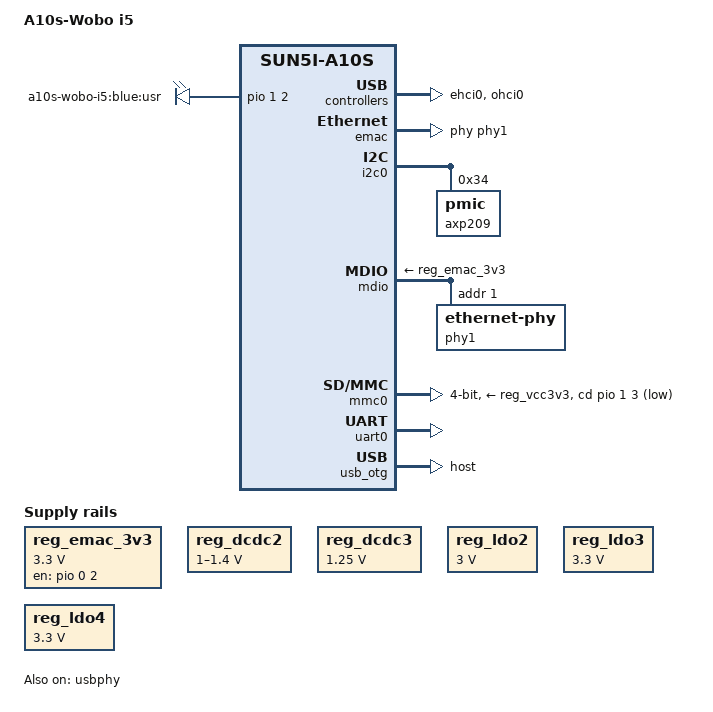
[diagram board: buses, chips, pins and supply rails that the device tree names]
/dts-v1/;
#include "sun5i-a10s.dtsi"
#include "sunxi-common-regulators.dtsi"
#include <dt-bindings/gpio/gpio.h>
#include <dt-bindings/interrupt-controller/irq.h>
/ {
	model = "A10s-Wobo i5";
	compatible = "wobo,a10s-wobo-i5", "allwinner,sun5i-a10s";
	aliases {
		serial0 = &uart0;
	};
	chosen {
		stdout-path = "serial0:115200n8";
	};
	leds {
		compatible = "gpio-leds";
		led {
			label = "a10s-wobo-i5:blue:usr";
			gpios = <&pio 1 2 GPIO_ACTIVE_HIGH>;
			default-state = "on";
		};
	};
	reg_emac_3v3: emac-3v3 {
		compatible = "regulator-fixed";
		regulator-name = "emac-3v3";
		regulator-min-microvolt = <3300000>;
		regulator-max-microvolt = <3300000>;
		startup-delay-us = <20000>;
		enable-active-high;
		gpio = <&pio 0 2 GPIO_ACTIVE_HIGH>;
	};
};
&cpu0 {
	cpu-supply = <&reg_dcdc2>;
};
&ehci0 {
	status = "okay";
};
&emac {
	pinctrl-names = "default";
	pinctrl-0 = <&emac_pd_pins>;
	phy-handle = <&phy1>;
	status = "okay";
};
&emac_sram {
	status = "okay";
};
&i2c0 {
	status = "okay";
	axp209: pmic@34 {
		reg = <0x34>;
		interrupts = <0>;
	};
};
#include "axp209.dtsi"
&mdio {
	phy-supply = <&reg_emac_3v3>;
	status = "okay";
	phy1: ethernet-phy@1 {
		reg = <1>;
	};
};
&mmc0 {
	vmmc-supply = <&reg_vcc3v3>;
	bus-width = <4>;
	cd-gpios = <&pio 1 3 GPIO_ACTIVE_LOW>;  
	status = "okay";
};
&ohci0 {
	status = "okay";
};
&otg_sram {
	status = "okay";
};
&reg_dcdc2 {
	regulator-always-on;
	regulator-min-microvolt = <1000000>;
	regulator-max-microvolt = <1400000>;
	regulator-name = "vdd-cpu";
};
&reg_dcdc3 {
	regulator-always-on;
	regulator-min-microvolt = <1250000>;
	regulator-max-microvolt = <1250000>;
	regulator-name = "vdd-int-dll";
};
&reg_ldo1 {
	regulator-name = "vdd-rtc";
};
&reg_ldo2 {
	regulator-always-on;
	regulator-min-microvolt = <3000000>;
	regulator-max-microvolt = <3000000>;
	regulator-name = "avcc";
};
&reg_ldo3 {
	regulator-always-on;
	regulator-min-microvolt = <3300000>;
	regulator-max-microvolt = <3300000>;
	regulator-name = "vcc-wifi1";
};
&reg_ldo4 {
	regulator-always-on;
	regulator-min-microvolt = <3300000>;
	regulator-max-microvolt = <3300000>;
	regulator-name = "vcc-wifi2";
};
&reg_usb1_vbus {
	gpio = <&pio 6 12 GPIO_ACTIVE_HIGH>;
	status = "okay";
};
&uart0 {
	pinctrl-names = "default";
	pinctrl-0 = <&uart0_pb_pins>;
	status = "okay";
};
&usb_otg {
	dr_mode = "host";
	status = "okay";
};
&usbphy {
	usb1_vbus-supply = <&reg_usb1_vbus>;
	status = "okay";
};
